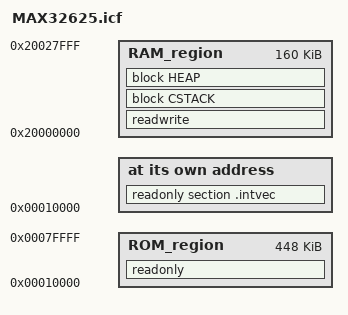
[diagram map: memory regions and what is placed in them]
if (!isdefinedsymbol(MBED_APP_START)) {
    define symbol MBED_APP_START = 0x00010000;
}
if (!isdefinedsymbol(MBED_APP_SIZE)) {
    define symbol MBED_APP_SIZE = 0x00070000;
}

/* [ROM] */
define symbol __intvec_start__        = MBED_APP_START;
define symbol __region_ROM_start__    = MBED_APP_START;
define symbol __region_ROM_end__      = MBED_APP_START + MBED_APP_SIZE - 1;

/* [RAM] Vector table dynamic copy: 68 vectors * 4 bytes = 272 (0x110) bytes */
define symbol __NVIC_start__          = 0x00010000;
define symbol __NVIC_end__            = 0x00010110; /* to be aligned on 8 bytes */
define symbol __region_RAM_start__    = 0x20000000;
define symbol __region_RAM_end__      = 0x20027FFF;

/* Memory regions */
define memory mem with size = 4G;
define region ROM_region      = mem:[from __region_ROM_start__   to __region_ROM_end__];
define region RAM_region      = mem:[from __region_RAM_start__   to __region_RAM_end__];

/* Stack and Heap */
if (!isdefinedsymbol(MBED_BOOT_STACK_SIZE)) {
    define symbol MBED_BOOT_STACK_SIZE = 0x400;
}

define symbol __size_cstack__ = MBED_BOOT_STACK_SIZE;
define symbol __size_heap__   = 0xA000;
define block CSTACK    with alignment = 8, size = __size_cstack__   { };
define block HEAP      with alignment = 8, size = __size_heap__     { };

initialize by copy { readwrite };
do not initialize  { section .noinit };

place at address mem:__intvec_start__ { readonly section .intvec };
place in ROM_region   { readonly };
place in RAM_region   { readwrite,
                        block CSTACK, block HEAP };
